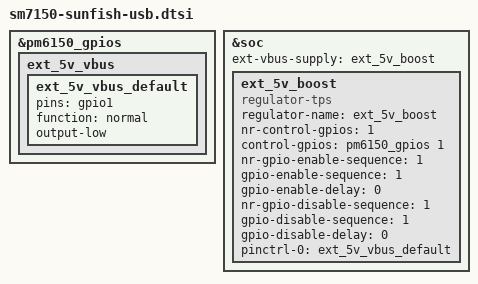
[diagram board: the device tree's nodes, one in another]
/* Copyright (c) 2019, The Linux Foundation. All rights reserved.
 *
 * This program is free software; you can redistribute it and/or modify
 * it under the terms of the GNU General Public License version 2 and
 * only version 2 as published by the Free Software Foundation.
 *
 * This program is distributed in the hope that it will be useful,
 * but WITHOUT ANY WARRANTY; without even the implied warranty of
 * MERCHANTABILITY or FITNESS FOR A PARTICULAR PURPOSE.  See the
 * GNU General Public License for more details.
 */

&pm6150_gpios {
	ext_5v_vbus {
		ext_5v_vbus_default: ext_5v_vbus_default {
			pins = "gpio1";
			function = "normal";
			output-low;
		};
	};
};

&soc {
	ext-vbus-supply = <&ext_5v_boost>;

	ext_5v_boost: ext_5v_boost {
		compatible = "regulator-tps";
		regulator-name = "ext_5v_boost";
		nr-control-gpios = <1>;
		control-gpios = <&pm6150_gpios 1 GPIO_ACTIVE_HIGH>;
		nr-gpio-enable-sequence = <1>;
		gpio-enable-sequence = <1>;
		gpio-enable-delay = <0>;
		nr-gpio-disable-sequence = <1>;
		gpio-disable-sequence = <1>;
		gpio-disable-delay = <0>;

		pinctrl-names = "default";
		pinctrl-0 = <&ext_5v_vbus_default>;

		status = "okay";
	};
};
